# MCU_NAVSS0_SEC_PROXY0_CFG register map
Vendor: Texas Instruments
Peripheral module from a debugger description file (folder am65x).
Registers are 32-bit, read-only, reset 0x66363100 unless marked. A register's access mark holds for its fields unless they carry their own. Offsets are as the file gives them; lines under a group give offsets from that group; [hi:lo] are bit positions; {n}, {i} and the like mark numbered series; 'fields as' and 'values as' point back to an identical list; <NAME> marks a mode.

## MCU_NAVSS0_SEC_PROXY0_CFG
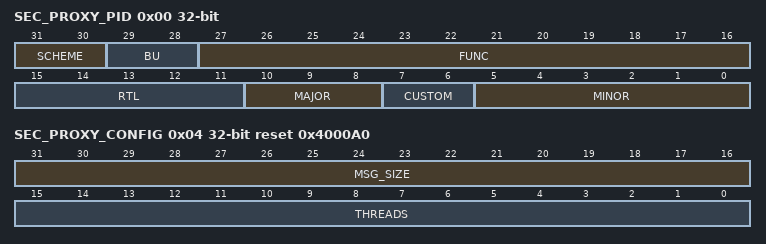
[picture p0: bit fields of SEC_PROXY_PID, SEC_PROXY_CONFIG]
0x00 SEC_PROXY_PID — The Revision Register contains the major and minor revisions for the module.
  [31:30] SCHEME — PID register scheme
  [29:28] BU
  [27:16] FUNC — Module ID
  [15:11] RTL — RTL revision.6h - SR1.0, Ch - SR2.0
  [10:8] MAJOR — Major revision
  [7:6] CUSTOM
  [5:0] MINOR — Minor revision
0x04 SEC_PROXY_CONFIG reset 0x4000A0 — The Config Register shows configured params.
  [31:16] MSG_SIZE — Supported message size in bytes.
  [15:0] THREADS — Number of proxy threads supported.
0x14 PROXY_GLB_EVT access per field reset 0xFFFF — The Global Event Register defines the event to send for a global error. SR2.0 Only.
  [15:0] ERR_EVENT rw — Global error event destination. 0xFFFF disables the event
